# CM41x_M0 register map
Vendor: Analog Devices; Series: CM41x_M0; File version: 1p0
CPU: CM0 r0p0, little endian, MPU, FPU, 4 interrupt priority bits
Registers are 32-bit, read-write, reset 0x0 unless marked. A register's access mark holds for its fields unless they carry their own. Offsets are from the block's base; [hi:lo] are bit positions; lines under a group give offsets from that group; {n}, {i} and the like mark numbered series; 'fields as' and 'values as' point back to an identical list.

## SMPU1 — The System Memory Protection Unit
Base 0x400E0000
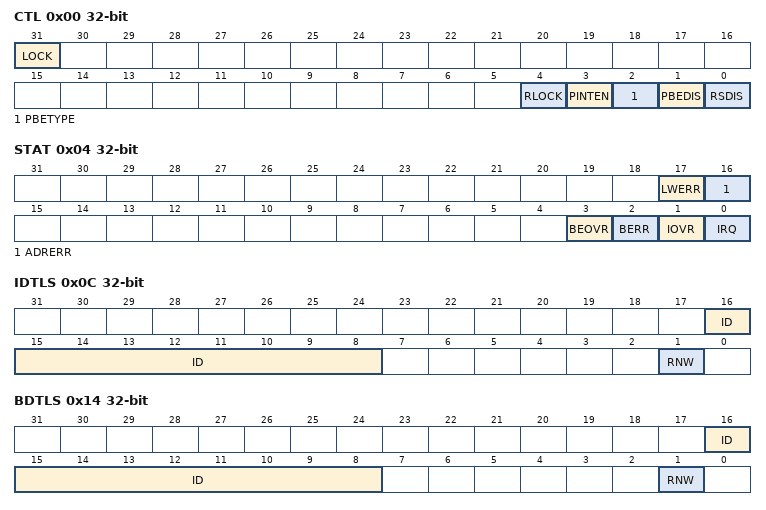
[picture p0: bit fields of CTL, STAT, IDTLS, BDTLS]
0x00 CTL — SMPU Control Register
  [31] LOCK — Lock Bit
  [4] RLOCK — RCTLn, RADDRn, RIDxn and RIDMxn Registers Lock Bit
  [3] PINTEN — Protection Violation Interrupt Enable
    0=PINTDIS (Protection Violation IRQ Disable.); 1=PINTEN (Protection Violation IRQ Enable.)
  [2] PBETYPE — Protection Violation Bus Error Type
    0=DECERR (Decode Error Type.); 1=SLVERR (Save Error Type.)
  [1] PBEDIS — Protection Violation Bus Error Disable
    0=PBEEN (Bus Error Generation Enable.); 1=PBEDIS (Bus Error Generation Disable.)
  [0] RSDIS — Read Speculation Disable
    0=RSEN (Read Speculation Enable.); 1=RSDIS (Read Speculation Disable.)
0x04 STAT — SMPU Status Register
  [17] LWERR — Lock Write Error
    0=NOLWERR (No Lock Write Error); 1=LWERR (Lock Write Error)
  [16] ADRERR — Address Error
    0=NOADRERR (No Address Error); 1=ADRERR (Address Error)
  [3] BEOVR — Bus Error Overrun
    0=NOBEOVR (No Bus Error overrun); 1=BEOVR (Bus Error overrun has occurred)
  [2] BERR — Bus Error
    0=NOBERR (No Bus Error since this bit has been cleared); 1=BERR (Bus Error has been generated)
  [1] IOVR — Interrupt Overrun
    0=NOIOVR (No Interrupt overrun); 1=IOVR (Interrupt overrun has occurred)
  [0] IRQ — Interrupt Request
    0=NOIRQ (No Interrupt since this bit has been cleared); 1=IRQ (Interrupt has been generated)
0x08 IADDR — Interrupt Address Register
  [31:0] VALUE ro — Interrupt Address
0x0C IDTLS — Interrupt Details Register
  [16:8] ID ro — ID of Transaction.
  [1] RNW ro — Read/Write Status.
    0=WRITE (Transaction that caused last signaled interrupt was a write); 1=READ (Transaction that caused last signaled interrupt was a read)
0x10 BADDR — Bus Error Address Register
  [31:0] VALUE ro — Bus Error Address
0x14 BDTLS — Bus Error Details Register
  [16:8] ID ro — ID of Transaction
  [1] RNW ro — Read/Write Status
    0=WRITE (Transaction that caused last bus error was a write); 1=READ (Transaction that caused last bus error was a read)
{0x20+0x18*i} SMPU1_Rn[{i}] (i=0..7) group — Region n
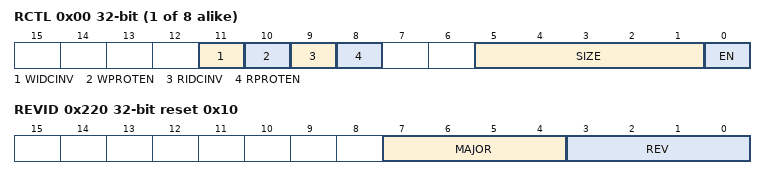
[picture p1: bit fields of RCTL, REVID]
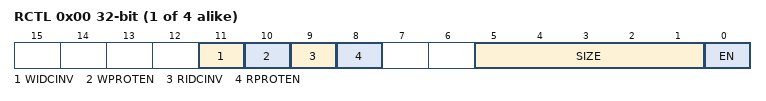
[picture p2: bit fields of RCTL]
  0x00 RCTL — Region n Control Register
    [11] WIDCINV — Write Transaction ID Compare Invert
    [10] WPROTEN — Write Transaction Protection Enable
      0=WPROTDIS (Write transaction ID-based protection disabled); 1=WPROTEN (Write transaction ID-based protection enabled)
    [9] RIDCINV — Read Transaction ID Compare Invert
    [8] RPROTEN — Read Transaction Protection Enable
      0=RPROTDIS (Read transaction ID-based protection disabled); 1=RPROTEN (Read transaction ID-based protection enabled)
    [5:1] SIZE — Memory Region Size
    [0] EN — Region Enable
  0x04 RADDR — Region n Address Register
    [31:12] BADDR range 0x00000000..0x000FFFFF — Region n Base Address 20 Most Significant Bits
  0x08 RIDA — Region n ID A Register
    [8:0] ID range 0x00000000..0x000001FF — Region n ID Register A
  0x0C RIDMSKA — Region n ID Mask A Register
    [8:0] MSK range 0x00000000..0x000001FF — Region n ID Mask Register A
  0x10 RIDB — Region n ID B Register
    [8:0] ID range 0x00000000..0x000001FF — Region n ID Register B
  0x14 RIDMSKB — Region n ID Mask B Register
    [8:0] MSK range 0x00000000..0x000001FF — Region n ID Mask Register B
0x220 REVID reset 0x10 — SMPU Revision ID Register
  [7:4] MAJOR ro — Major Version ID
  [3:0] REV ro — Incremental Version ID

## SMPU2 — The System Memory Protection Unit
Base 0x400E1000
Registers as SMPU1, without SMPU1_Rn[*]; these are added or differ:
{0x20+0x18*i} SMPU2_Rn[{i}] (i=0..3) group — Region n
  0x00 RCTL — Region n Control Register
    fields as SMPU1.SMPU1_Rn[0].RCTL
  0x04 RADDR — Region n Address Register
    [31:12] BADDR range 0x00000000..0x000FFFFF — Region n Base Address 20 Most Significant Bits
  0x08 RIDA — Region n ID A Register
    [8:0] ID range 0x00000000..0x000001FF — Region n ID Register A
  0x0C RIDMSKA — Region n ID Mask A Register
    [8:0] MSK range 0x00000000..0x000001FF — Region n ID Mask Register A
  0x10 RIDB — Region n ID B Register
    [8:0] ID range 0x00000000..0x000001FF — Region n ID Register B
  0x14 RIDMSKB — Region n ID Mask B Register
    [8:0] MSK range 0x00000000..0x000001FF — Region n ID Mask Register B
